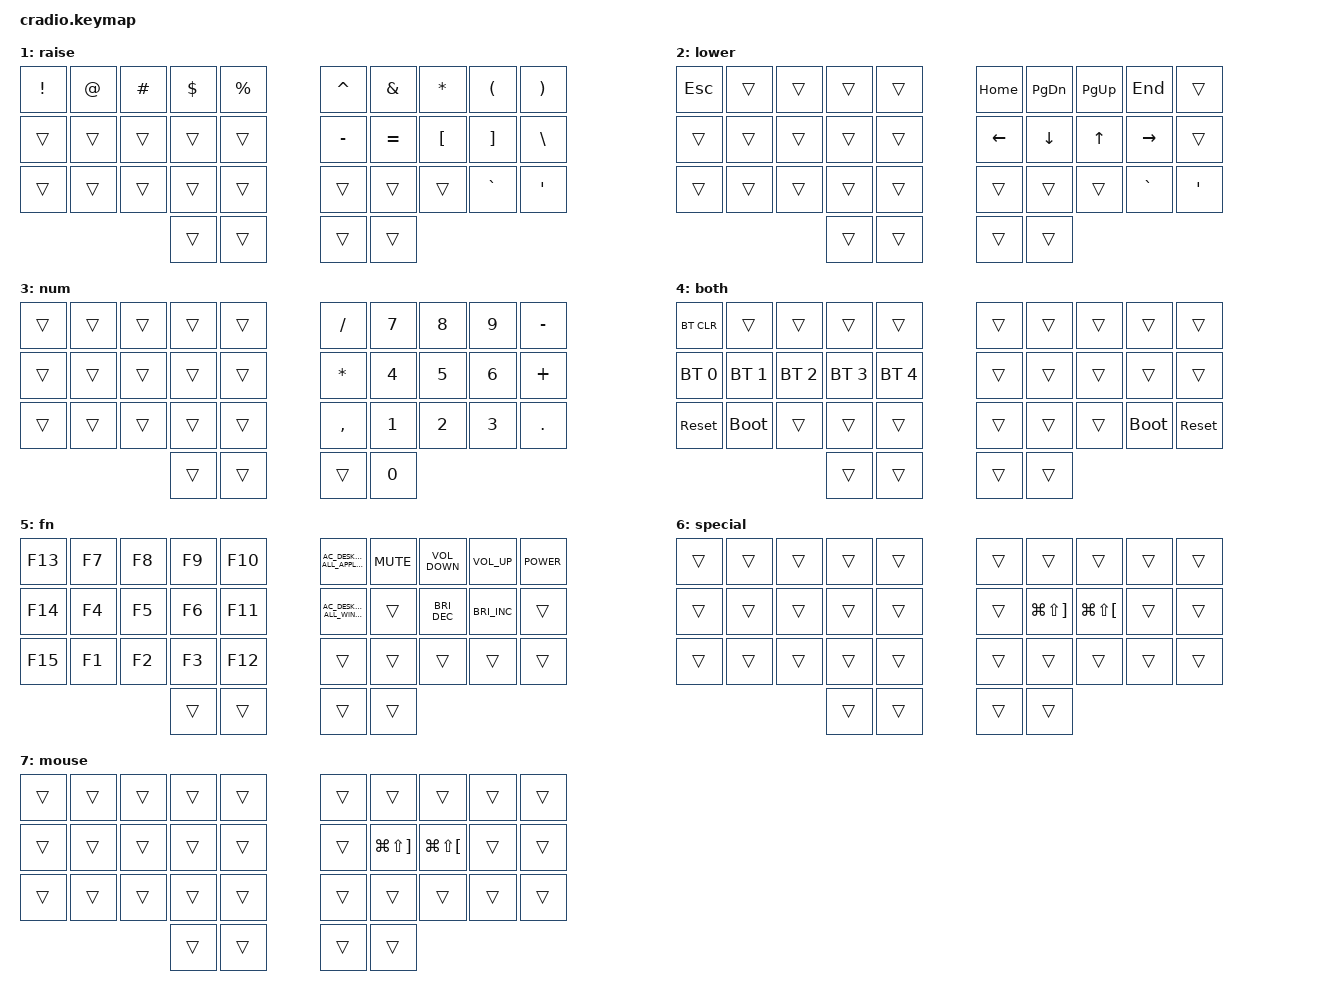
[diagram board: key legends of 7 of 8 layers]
// Copyright (c) 2022 The ZMK Contributors
// SPDX-License-Identifier: MIT

#define ZMK_POINTING_DEFAULT_MOVE_VAL 1500  // default: 600
#define ZMK_POINTING_DEFAULT_SCRL_VAL 20    // default: 10

#include <behaviors.dtsi>
#include <behaviors/mouse_keys.dtsi>
#include <dt-bindings/zmk/bt.h>
#include <dt-bindings/zmk/keys.h>
// #include <dt-bindings/zmk/outputs.h>
#include <dt-bindings/zmk/pointing.h>


// Home row mods macro
#define HRML(k1,k2,k3,k4) &ht LSHFT k1  &ht LALT k2  &ht LCTRL k3  &ht LGUI k4
#define HRMR(k1,k2,k3,k4) &ht RGUI k1  &ht RCTRL k2  &ht RALT k3  &ht RSHFT k4

&mmv {
    x-input-code = <INPUT_REL_X>;
    y-input-code = <INPUT_REL_Y>;
    time-to-max-speed-ms = <300>;
    acceleration-exponent = <1>;
};

&msc {
    x-input-code = <INPUT_REL_HWHEEL>;
    y-input-code = <INPUT_REL_WHEEL>;
    time-to-max-speed-ms = <300>;
    acceleration-exponent = <0>;
};

/ {
    combos {
        compatible = "zmk,combos";

        esc {
            timeout-ms = <50>;
            key-positions = <0 1>;
            bindings = <&kp ESC>;
        };

        tab {
            key-positions = <12 13>;
            bindings = <&kp TAB>;
        };

        caps_word {
            key-positions = <14 15>;
            bindings = <&caps_word>;
        };

        delete {
            key-positions = <27 28>;
            bindings = <&kp DELETE>;
        };

        backspace {
            bindings = <&kp BACKSPACE>;
            key-positions = <17 18>;
        };

        leader_leader_s {
            bindings = <&leader_leader_s>;
            key-positions = <13 16>;
        };

        cmd_shift {
            bindings = <&kp LS(LCMD)>;
            key-positions = <10 30>;
        };
    };

    macros {
        leader_leader_s: leader_leader {
        compatible = "zmk,behavior-macro";
        #binding-cells = <0>;
        bindings = <&kp ESCAPE &kp SPACE &kp SPACE &kp S>;
        label = "LEADER_LEADER";
        };
    };

    
    behaviors {
        ht: hold_tap {
            compatible = "zmk,behavior-hold-tap";
            #binding-cells = <2>;
            flavor = "tap-preferred";
            tapping-term-ms = <220>;
            quick-tap-ms = <150>;
            require-prior-idle-ms = <100>;
            bindings = <&kp>, <&kp>;
        };
        ht2: hold_tap_2 {
            compatible = "zmk,behavior-hold-tap";
            #binding-cells = <2>;
            flavor = "tap-preferred";
            tapping-term-ms = <220>;
            quick-tap-ms = <150>;
            require-prior-idle-ms = <100>;
            bindings = <&sl>, <&kp>;
        };
        
        ht2hold: hold_tap_2_hold_preferred {
            compatible = "zmk,behavior-hold-tap";
            #binding-cells = <2>;
            flavor = "hold-preferred";
            tapping-term-ms = <220>;
            quick-tap-ms = <150>;
            require-prior-idle-ms = <100>;
            bindings = <&sl>, <&kp>;
        };
    };

    conditional_layers {
        compatible = "zmk,conditional-layers";
        tri_layer {
            if-layers = <1 2>;
            then-layer = <4>;
        };
    };

    keymap {
        compatible = "zmk,keymap";
        default_layer {
            bindings = <
        //╭──────────┬──────────┬──────────┬──────────┬──────────╮   ╭──────────┬──────────┬──────────┬──────────┬──────────╮
        //│  Q       │  W       │  E       │  R       │  T       │   │  Y       │  U       │  I       │  O       │  P       │
            &kp Q      &kp W      &kp E      &kp R      &kp T          &kp Y      &kp U      &kp I      &kp O      &kp P
        //├──────────┼──────────┼──────────┼──────────┼──────────┤   ├──────────┼──────────┼──────────┼──────────┼──────────┤
        //│  A       │  S       │  D       │  F       │  G       │   │  H       │  J       │  K       │  L       │ ; :      │
            HRML(A,        S,         D,         F)     &kp G          &kp H      HRMR(J,     K,         L,        SEMI)
        //├──────────┼──────────┼──────────┼──────────┼──────────┤   ├──────────┼──────────┼──────────┼──────────┼──────────┤
        //│  Z       │  X       │  C       │  V       │  B       │   │  N       │  M       │ , <      │ . >      │ / ?      │
            &kp Z      &ht2 3 X   &kp C      &kp V      &kp B          &kp N      &kp M      &kp COMMA  &ht2 5 DOT &ht2hold 7  FSLH
        //╰──────────┴──────────┴──────────┼──────────┼──────────┤   ├──────────┼──────────┼──────────┴──────────┴──────────╯
                                            &ht2hold 6 TAB   &sl 1   &ht2hold 2 ENTER  &kp SPACE 
        //                                 ╰──────────┴──────────╯   ╰──────────┴──────────╯
            >;
        };

        raise {
        bindings = <
            &kp EXCL  &kp AT  &kp HASH  &kp DLLR  &kp PRCNT    &kp CARET  &kp AMPS   &kp STAR  &kp LPAR   &kp RPAR
            &trans      &trans  &trans    &trans    &trans       &kp MINUS  &kp EQUAL  &kp LBKT  &kp RBKT   &kp BSLH
            &trans      &trans  &trans    &trans    &trans       &trans     &trans     &trans    &kp GRAVE  &kp APOS
                                          &trans    &trans       &trans     &trans
        >;
        };

        lower {
        bindings = <
            &kp ESCAPE  &trans  &trans  &trans  &trans    &kp HOME        &kp PG_DN       &kp PG_UP     &kp END          &trans
            &trans      &trans  &trans  &trans  &trans    &kp LEFT_ARROW  &kp DOWN_ARROW  &kp UP_ARROW  &kp RIGHT_ARROW  &trans
            &trans      &trans  &trans  &trans  &trans    &trans          &trans          &trans        &kp GRAVE        &kp APOS
                                        &trans  &trans    &trans          &trans
        >;
        };

        num {
        bindings = <
            &trans  &trans  &trans  &trans  &trans    &kp SLASH     &kp NUMBER_7  &kp NUMBER_8  &kp NUMBER_9  &kp MINUS
            &trans  &trans  &trans  &trans  &trans    &kp ASTERISK  &kp NUMBER_4  &kp NUMBER_5  &kp NUMBER_6  &kp PLUS
            &trans  &trans  &trans  &trans  &trans    &kp COMMA     &kp NUMBER_1  &kp NUMBER_2  &kp NUMBER_3  &kp PERIOD
                                    &trans  &trans    &trans        &kp NUMBER_0
        >;
        };

        both {
        bindings = <
            &bt BT_CLR    &trans        &trans        &trans        &trans        &trans  &trans  &trans  &trans       &trans
            &bt BT_SEL 0  &bt BT_SEL 1  &bt BT_SEL 2  &bt BT_SEL 3  &bt BT_SEL 4  &trans  &trans  &trans  &trans       &trans
            &sys_reset    &bootloader   &trans        &trans        &trans        &trans  &trans  &trans  &bootloader  &sys_reset
                                                      &trans        &trans        &trans  &trans
        >;
        };

        fn {
        bindings = <
            &kp F13  &kp F7  &kp F8  &kp F9  &kp F10    &kp C_AC_DESKTOP_SHOW_ALL_APPLICATIONS  &kp C_MUTE            &kp C_VOLUME_DOWN     &kp C_VOLUME_UP        &kp C_POWER
            &kp F14  &kp F4  &kp F5  &kp F6  &kp F11    &kp C_AC_DESKTOP_SHOW_ALL_WINDOWS       &trans                &kp C_BRIGHTNESS_DEC  &kp C_BRIGHTNESS_INC  &trans
            &kp F15  &kp F1  &kp F2  &kp F3  &kp F12    &trans                                  &trans                &trans                &trans  &trans
                                     &trans  &trans     &trans                                  &trans
        >;
        };

        //special {
        //bindings = <
        //    &kp ESCAPE  &kp LG(W)    &kp LG(E)  &kp LG(R)  &kp LG(T)    &trans         &trans        &trans         &kp LG(O)      &kp LG(P)
        //    &kp LG(A)   &kt LG(TAB)  &trans     &kp LG(F)  &kp LG(G)    &kp LG(MINUS)  &kp LG(PLUS)  &kp LG(K)      &kp LG(L)      &trans
        //    &kp LG(Z)   &kp LG(X)    &kp LG(C)  &kp LG(V)  &kp LG(B)    &trans         &trans        &trans         &kp LG(GRAVE)  &kp LG(APOS)
        //                                        &trans     &trans       &trans         &trans
        //>;
        //};
        
        special {
        bindings = <
            &trans   &trans    &trans  &trans  &trans   &trans  &trans            &trans             &trans    &trans
            &trans   &trans    &trans  &trans  &trans   &trans  &kp LG(LS(RBKT))  &kp LG(LS(LBKT))   &trans    &trans
            &trans   &trans    &trans  &trans  &trans   &trans  &trans            &trans             &trans    &trans
                                       &trans  &trans   &trans  &trans
        >;
        };

        mouse {
        bindings = <
            &trans   &trans    &trans  &trans  &trans   &trans  &trans            &trans             &trans    &trans
            &trans   &trans    &trans  &trans  &trans   &trans  &kp LG(LS(RBKT))  &kp LG(LS(LBKT))   &trans    &trans
            &trans   &trans    &trans  &trans  &trans   &trans  &trans            &trans             &trans    &trans
                                       &trans  &trans   &trans  &trans
        >;
        };
    };
};
